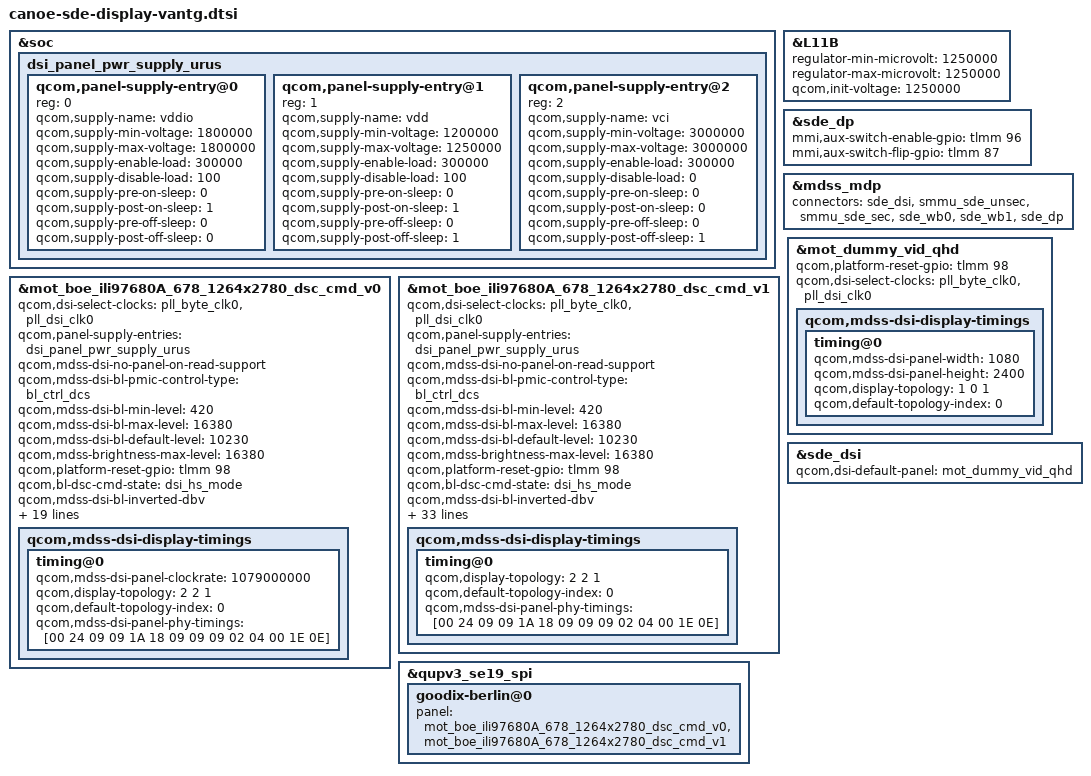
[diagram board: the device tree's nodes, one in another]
// SPDX-License-Identifier: BSD-3-Clause
/*
 * Copyright (c) 2024-2025, Qualcomm Innovation Center, Inc. All rights reserved.
 */

#include "canoe-sde-display.dtsi"
#include "dsi-panel-mot-dummy-qhd-video.dtsi"
#include "dsi-panel-mot-boe-ili97680A-678-1264x2780-dsc-cmd-common_v0.dtsi"
#include "dsi-panel-mot-boe-ili97680A-678-1264x2780-dsc-cmd-common_v1.dtsi"

&soc {
	dsi_panel_pwr_supply_urus: dsi_panel_pwr_supply_urus {
		#address-cells = <1>;
		#size-cells = <0>;

	qcom,panel-supply-entry@0 {
		reg = <0>;
		qcom,supply-name = "vddio";
		qcom,supply-min-voltage = <1800000>;
		qcom,supply-max-voltage = <1800000>;
		qcom,supply-enable-load = <300000>;
		qcom,supply-disable-load = <100>;
		qcom,supply-pre-on-sleep = <0>;
		qcom,supply-post-on-sleep = <1>;
		qcom,supply-pre-off-sleep = <0>;
		qcom,supply-post-off-sleep = <0>;
        };
	qcom,panel-supply-entry@1 {
		reg = <1>;
		qcom,supply-name = "vdd";
		qcom,supply-min-voltage = <1200000>;
		qcom,supply-max-voltage = <1250000>;
		qcom,supply-enable-load = <300000>;
		qcom,supply-disable-load = <100>;
		qcom,supply-pre-on-sleep = <0>;
		qcom,supply-post-on-sleep = <1>;
		qcom,supply-pre-off-sleep = <0>;
		qcom,supply-post-off-sleep = <1>;
        };

        qcom,panel-supply-entry@2 {
		reg = <2>;
		qcom,supply-name = "vci";
		qcom,supply-min-voltage = <3000000>;
		qcom,supply-max-voltage = <3000000>;
		qcom,supply-enable-load = <300000>;
		qcom,supply-disable-load = <0>;
		qcom,supply-pre-on-sleep = <0>;
		qcom,supply-post-on-sleep = <0>;
		qcom,supply-pre-off-sleep = <0>;
		qcom,supply-post-off-sleep = <1>;
        };
	};
};

&L11B {
       regulator-min-microvolt = <1250000>;
       regulator-max-microvolt = <1250000>;
       qcom,init-voltage = <1250000>;
};

&sde_dp {
	mmi,aux-switch-enable-gpio = <&tlmm 96 0>;
	mmi,aux-switch-flip-gpio = <&tlmm 87 0>;
};

&mdss_mdp {
	connectors = <&sde_dsi &smmu_sde_unsec &smmu_sde_sec &sde_wb0 &sde_wb1 &sde_dp>;
};

&mot_boe_ili97680A_678_1264x2780_dsc_cmd_v0 {
	qcom,dsi-select-clocks = "pll_byte_clk0", "pll_dsi_clk0";
	qcom,panel-supply-entries = <&dsi_panel_pwr_supply_urus>;
	qcom,mdss-dsi-no-panel-on-read-support;
	qcom,mdss-dsi-bl-pmic-control-type = "bl_ctrl_dcs";
	qcom,mdss-dsi-bl-min-level = <420>;
	qcom,mdss-dsi-bl-max-level = <16380>;
	qcom,mdss-dsi-bl-default-level = <10230>;
	qcom,mdss-brightness-max-level = <16380>;
	qcom,platform-reset-gpio = <&tlmm 98 0>;
	qcom,bl-dsc-cmd-state = "dsi_hs_mode";
	qcom,mdss-dsi-bl-inverted-dbv;
	qcom,mdss-dsi-bl-is-exponent;

	qcom,mdss-dsi-panel-status-check-mode = "reg_read";
	qcom,mdss-dsi-panel-status-command = [06 01 00 01 00 00 01 0a];
	qcom,mdss-dsi-panel-status-command-state = "dsi_lp_mode";
	qcom,mdss-dsi-panel-status-value = <0x9c>;
	qcom,mdss-dsi-panel-status-read-length = <1>;
	//qcom,esd-check-enabled;
	qcom,cellid-read-enabled;
	qcom,mdss-dsi-panel-cellid-read-length = <36>;
	qcom,mdss-dsi-panel-cellid-offset = <13>;
	qcom,mdss-dsi-panel-cellid-command = [
		06 01 00 01 00 00 01 AC];

	qcom,mdss-dsi-panel-hdr-enabled;
	qcom,mdss-dsi-panel-hdr-color-primaries = <15600 16450 34000
	        16000 13250 34500 7500 3000>;
	qcom,mdss-dsi-panel-peak-brightness = <15000000>;
	qcom,mdss-dsi-panel-blackness-level = <1>;

	/*qcom,apl-enabled;
	qcom,mdss-dsi-panel-APL-THRESHOLD-BL = <14258>;
	qcom,mdss-dsi-panel-apl-on-command = [
		39 00 00 00 00 00 03 5F 00 01];
	qcom,mdss-dsi-panel-apl-off-command = [
		39 00 00 00 00 00 03 5F 00 00];*/

	//qcom,ulps-enabled;
	qcom,mdss-dsi-display-timings {
		timing@0 { //120
			//qcom,framerate-group-no-duplicated;
			//qcom,framerate-group-120hz-based;
			//qcom,partial-update-enabled = "single_roi";
			//qcom,panel-roi-alignment = <1224 160 1224 160 1224 160>;
			qcom,mdss-dsi-panel-clockrate = <1079000000>;
			qcom,display-topology = <2 2 1>;
			qcom,default-topology-index = <0>;
			qcom,mdss-dsi-panel-phy-timings = [00 24 09 09 1A 18 09
							09 09 02 04 00 1E 0E];
		};
	};
};

&mot_boe_ili97680A_678_1264x2780_dsc_cmd_v1 {
	qcom,dsi-select-clocks = "pll_byte_clk0", "pll_dsi_clk0";
	qcom,panel-supply-entries = <&dsi_panel_pwr_supply_urus>;
	qcom,mdss-dsi-no-panel-on-read-support;
	qcom,mdss-dsi-bl-pmic-control-type = "bl_ctrl_dcs";
	qcom,mdss-dsi-bl-min-level = <420>;
	qcom,mdss-dsi-bl-max-level = <16380>;
	qcom,mdss-dsi-bl-default-level = <10230>;
	qcom,mdss-brightness-max-level = <16380>;
	qcom,platform-reset-gpio = <&tlmm 98 0>;
	qcom,bl-dsc-cmd-state = "dsi_hs_mode";
	qcom,mdss-dsi-bl-inverted-dbv;
	qcom,mdss-dsi-bl-is-exponent;

	qcom,mdss-dsi-panel-status-check-mode = "reg_read";
	qcom,mdss-dsi-panel-status-command = [06 01 00 01 00 00 01 0a];
	qcom,mdss-dsi-panel-status-command-state = "dsi_lp_mode";
	qcom,mdss-dsi-panel-status-value = <0x9c>;
	qcom,mdss-dsi-panel-status-read-length = <1>;
	//qcom,esd-check-enabled;
	qcom,cellid-read-enabled;
	qcom,mdss-dsi-panel-cellid-send-command-enabled;
	qcom,mdss-dsi-panel-cellid-send-command = [
		39 00 00 00 00 00 04 FF 5A A5 1D];
	qcom,mdss-dsi-panel-cellid-read-length = <23>;
	qcom,mdss-dsi-panel-cellid-offset = <0>;
	qcom,mdss-dsi-panel-cellid-command = [
		06 01 00 01 00 00 01 80];
	qcom,mdss-dsi-panel-cellid-send-back-command = [
		39 00 00 00 00 00 04 FF 5A A5 00];

	qcom,mdss-dsi-panel-hdr-enabled;
	qcom,mdss-dsi-panel-hdr-color-primaries = <15600 16450 34000
	        16000 13250 34500 7500 3000>;
	qcom,mdss-dsi-panel-peak-brightness = <15000000>;
	qcom,mdss-dsi-panel-blackness-level = <1>;

	qcom,apl-enabled;
	qcom,mdss-dsi-panel-APL-THRESHOLD-BL = <16000>;
	qcom,mdss-dsi-panel-APL-FUNC-ID = <0>;
	qcom,mdss-dsi-panel-apl-on-command = [
		39 00 00 40 00 00 04 FF 5A A5 1F
		39 00 00 40 00 00 1f C3 FA FF FF E9 E9 AA E9 E9 E9 E9 AA E9 E9 E9 E9 AA E9 E9 E9 E9 AA E9 E9 E9 E9 AA E9 E9 E9 E9
		39 00 00 40 00 00 04 FF 5A A5 1E
		39 00 00 40 00 00 02 9A 13
		39 00 00 40 00 00 02 80 A9
		39 00 00 00 00 00 04 FF 5A A5 00];
	qcom,mdss-dsi-panel-apl-off-command = [
		39 00 00 40 00 00 04 FF 5A A5 1F
		39 00 00 40 00 00 1f C3 FA FF FF E9 E9 AA E9 E9 E9 E9 AA E9 E9 E9 E9 AA E9 E9 E9 E9 AA E9 E9 E9 E9 AA E9 E9 E9 E9
		39 00 00 40 00 00 04 FF 5A A5 1E
		39 00 00 40 00 00 02 9A 13
		39 00 00 40 00 00 02 80 89
		39 00 00 00 00 00 04 FF 5A A5 00];

	//qcom,ulps-enabled;
	qcom,qsync-enable;
	qcom,mdss-dsi-qsync-min-refresh-rate = <1>;
	//qcom,mdss-disable-cesta-hw-sleep;
	qcom,mdss-dsi-display-timings {
		timing@0 { //120
			//qcom,mdss-dsi-panel-clockrate = <1079000000>;
			qcom,display-topology = <2 2 1>;
			qcom,default-topology-index = <0>;
			qcom,mdss-dsi-panel-phy-timings = [00 24 09 09 1A 18 09
							09 09 02 04 00 1E 0E];
		};
	};
};

&mot_dummy_vid_qhd {
       qcom,mdss-dsi-display-timings {
                timing@0{
                       qcom,mdss-dsi-panel-width = <1080>;
                       qcom,mdss-dsi-panel-height = <2400>;
               };
       };
};

&mot_dummy_vid_qhd {
	qcom,platform-reset-gpio = <&tlmm 98 0>;

	qcom,dsi-select-clocks = "pll_byte_clk0", "pll_dsi_clk0";
	qcom,mdss-dsi-display-timings {
		timing@0 {
			qcom,display-topology = <1 0 1>;
			qcom,default-topology-index = <0>;
		};
	};
};

&sde_dsi {
	qcom,dsi-default-panel = <&mot_dummy_vid_qhd>;
};

&qupv3_se19_spi {
	goodix-berlin@0 {
		panel = <&mot_boe_ili97680A_678_1264x2780_dsc_cmd_v0
		&mot_boe_ili97680A_678_1264x2780_dsc_cmd_v1>;
	};
};
